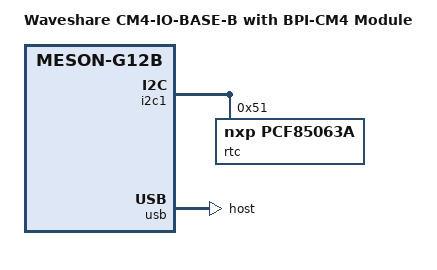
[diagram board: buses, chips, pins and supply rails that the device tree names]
// SPDX-License-Identifier: (GPL-2.0+ OR MIT)
/*
 * Copyright (c) 2023 Patrick Yavitz <pyavitz@xxxxx.com>
 * See https://www.waveshare.com/wiki/CM4-IO-BASE-B
 */

/dts-v1/;

#include "meson-g12b-bananapi-cm4-cm4io.dts"

/ {
	compatible = "bananapi,bpi-cm4io", "bananapi,bpi-cm4", "amlogic,a311d", "amlogic,g12b";
	model = "Waveshare CM4-IO-BASE-B with BPI-CM4 Module";

	aliases {
		rtc0 = &rtc;
	};
};

&i2c1 {
	rtc: rtc@51 {
		compatible = "nxp,pcf85063a";
		reg = <0x51>;
		wakeup-source;
	};
};

&usb {
	dr_mode = "host";
};
